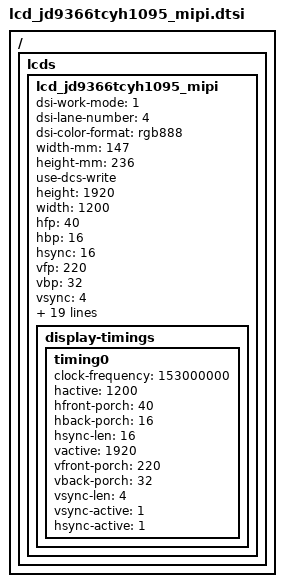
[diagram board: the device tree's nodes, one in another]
// SPDX-License-Identifier: GPL-2.0

/ { lcds: lcds {
	lcd_jd9366tcyh1095_mipi: lcd_jd9366tcyh1095_mipi {
		dsi-work-mode = <1>; /* video burst mode */
		dsi-lane-number = <4>;
		dsi-color-format = "rgb888";
		width-mm = <147>;
		height-mm = <236>;
		use-dcs-write;

		/* mipi info */
		height = <1920>;
		width = <1200>;
		hfp = <40>;
		hbp = <16>;
		hsync = <16>;
		vfp = <220>;
		vbp = <32>;
		vsync = <4>;
		fps = <60>;
		work-mode = <0>;
		rgb-mode = <3>;
		lane-number = <4>;
		phy-bit-clock = <1000000000>;
		phy-esc-clock = <76800000>;
		split-enable = <0>;
		eotp-enable = <0>;
		burst-mode = <2>;
		esd-check-enable = <0>;
		esd-check-value = <0x18>;

		/* DSI_CMD, DSI_MODE, timeout, len, cmd */
		initial-command = [
			39 01 00 04 df 93 86 19
			39 01 00 02 de 00
			39 01 00 07 b2 01 23 60 55 88 db
			39 01 00 07 b6 08 00 00 00 30 00
			39 01 00 0b bb 00 42 00 83 46 33 33 33 00 5a
			39 01 00 03 bd 00 37
			39 01 00 09 bf 53 e7 30 00 63 03 8d 00
			39 01 00 06 c0 11 22 01 22 01
			39 01 00 31 c3 03 01 42 07 00 00 00 00 01 01 01 01 01 01 02 08 01 01 01 08 a0 71 71 71 71 01 a0 71 71 71 01 a0 71 00 01 06 01 06 01 06 08 0e 0a 10 0a 10 04 57
			39 01 00 23 c4 01 02 00 00 10 01 01 01 02 08 01 01 01 08 a0 71 01 a0 01 a0 01 06 01 06 01 06 08 0e 01 06 01 06 04 57
			39 01 00 18 c6 01 58 00 dc 00 28 16 82 01 00 00 01 00 01 00 00 00 00 00 10 00 00 01
			39 01 00 03 c8 3b 80
			39 01 00 03 c9 0b 00
			39 01 00 44 ce 00 00 00 00 00 00 00 00 00 00 00 00 00 00 00 00 00 00 00 00 00 00 00 00 00 00 00 00 00 00 00 00 00 00 00 00 00 00 00 00 00 00 00 00 00 05 05 05 05 05 05 05 05 05 05 05 05 05 05 05 05 05 05 05 05 05 05
			39 01 00 2e cf 00 30 30 30 30 30 30 30 30 30 30 30 30 30 30 30 30 30 30 30 30 30 30 00 00 00 00 00 00 00 00 00 00 00 00 00 00 00 00 00 00 00 00 00 00
			39 01 00 18 d0 00 96 94 aa ab ab 9e 9f 2b 84 86 88 8a 8c 8e 90 92 82 80 2b 2b 2b 2b
			39 01 00 18 d1 00 97 95 aa ab ab 9e 9f 2b 85 87 89 8b 8d 8f 91 93 83 81 2b 2b 2b 2b
			39 01 00 18 d2 00 01 03 2b 2a 2b 1e 1f 2b 13 11 0f 0d 0b 09 07 05 15 17 2b 2b 2b 2b
			39 01 00 18 d3 00 00 02 2b 2a 2b 1e 1f 2b 12 10 0e 0c 0a 08 06 04 14 16 2b 2b 2b 2b
			39 01 00 17 d4 30 00 00 00 18 1c 00 00 00 00 99 00 d0 00 77 ae b0 00 01 04 04 04
			39 01 00 45 d5 03 00 30 00 00 00 01 00 00 00 e0 00 00 00 07 32 5a 10 0e 01 00 03 00 01 f6 00 1c 10 00 00 00 00 71 00 04 10 00 00 00 00 00 00 00 05 08 02 02 00 1b 00 00 00 00 00 00 00 00 00 00 00 00 00 00 00 00 00 00 00
			39 01 00 12 d7 00 98 80 80 80 80 80 80 80 80 80 80 80 a0 80 a0 80
			39 01 00 02 de 01
			39 01 00 04 c8 04 01 04
			39 01 00 02 b9 01
			39 01 00 30 c2 00 00 05 55 55 6a aa bf ff f0 20 20 28 41 73 9a bb d7 ef 04 18 39 55 6d 83 96 a8 b9 c8 e7 05 24 46 6c 97 ae c9 e7 0a 33 65 84 a7 bc d3 ee fc
			39 01 00 30 c3 00 00 05 55 55 6a aa bf ff f0 20 20 28 41 73 9a bb d7 ef 04 18 39 55 6d 83 96 a8 b9 c8 e7 05 24 46 6c 97 ae c9 e7 0a 33 65 84 a7 bc d3 ee fc
			39 01 00 30 c4 00 00 05 55 55 6a aa bf ff f0 20 20 28 41 73 9a bb d7 ef 04 18 39 55 6d 83 96 a8 b9 c8 e7 05 24 46 6c 97 ae c9 e7 0a 33 65 84 a7 bc d3 ee fc
			39 01 00 30 c5 00 00 05 55 55 6a aa bf ff f0 20 20 28 41 73 9a bb d7 ef 04 18 39 55 6d 83 96 a8 b9 c8 e7 05 24 46 6c 97 ae c9 e7 0a 33 65 84 a7 bc d3 ee fc
			39 01 00 30 c6 00 00 05 55 55 6a aa bf ff f0 20 20 28 41 73 9a bb d7 ef 04 18 39 55 6d 83 96 a8 b9 c8 e7 05 24 46 6c 97 ae c9 e7 0a 33 65 84 a7 bc d3 ee fc
			39 01 00 30 c7 00 00 05 55 55 6a aa bf ff f0 20 20 28 41 73 9a bb d7 ef 04 18 39 55 6d 83 96 a8 b9 c8 e7 05 24 46 6c 97 ae c9 e7 0a 33 65 84 a7 bc d3 ee fc
			39 01 00 0e c9 05 7f 00 55 55 55 99 99 99 00 00 40 00
			39 01 00 02 de 02
			39 01 00 0a c2 02 42 d0 02 00 c4 61 73 fb
			39 01 00 06 c4 02 11 07 00 1a
			39 01 00 07 c5 07 ff ff 07 ff ff
			39 01 00 03 c6 40 06
			39 01 00 0a d6 03 40 01 01 0d 40 10 64 70
			39 01 00 04 e6 10 0a c8
			39 01 00 05 ee 10 01 10 00
			39 01 00 02 de 03
			39 01 00 03 d1 05 10
			39 01 00 02 de 04
			39 01 00 06 cd 20 04 21 10 33
			39 01 00 08 ce 00 28 50 0a 5a 00 00
			39 01 00 02 de 07
			39 01 00 02 de 00
			39 01 00 05 b3 01 00 00 88
			// 39 01 00 02 c2 60
			39 01 78 02 11 00
			39 01 20 02 29 00
			39 01 00 02 35 00
		];

		sleep-in-command = [
			39 01 20 02 28 00
			39 01 78 02 10 00
		];
		sleep-out-command = [
			39 01 78 02 11 00
			39 01 20 02 29 00
		];
		read-id-command = [
			37 01 00 01 01
			14 01 00 01 04
		];

		display-timings {
			timing0 {
				clock-frequency = <153000000>;
				hactive = <1200>;
				hfront-porch = <40>;
				hback-porch = <16>;
				hsync-len = <16>;
				vactive = <1920>;
				vfront-porch = <220>;
				vback-porch = <32>;
				vsync-len = <4>;
				vsync-active = <1>;
				hsync-active = <1>;
			};
		};
	};
};};
